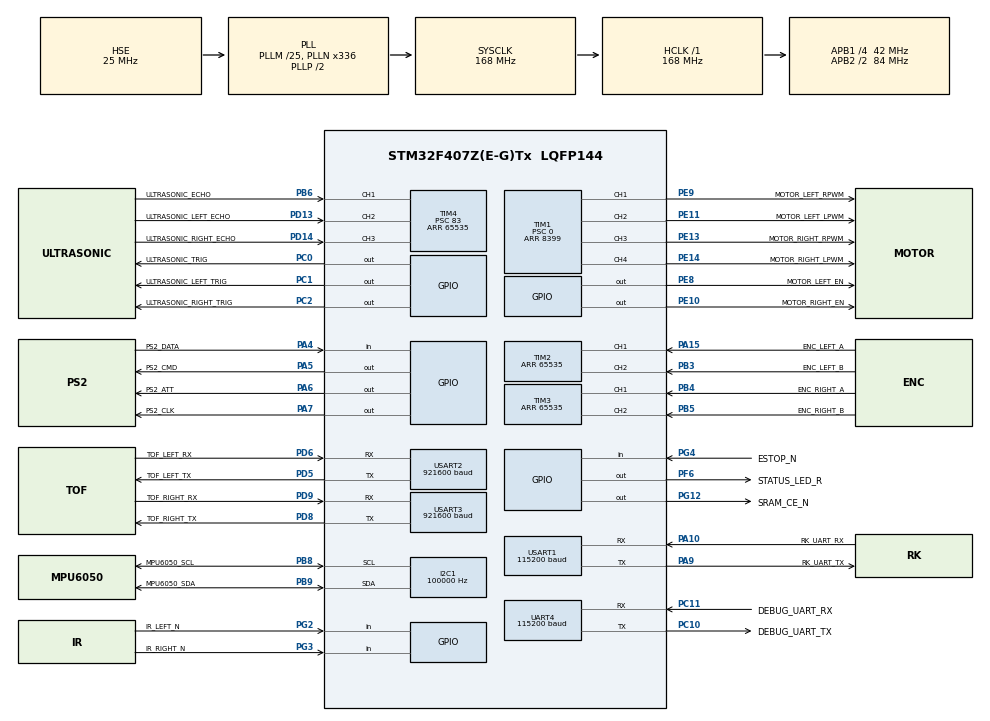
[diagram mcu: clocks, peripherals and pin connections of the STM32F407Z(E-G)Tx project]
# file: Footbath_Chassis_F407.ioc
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I2C1.Analog_Filter=I2C_ANALOGFILTER_ENABLE
I2C1.ClockSpeed=100000
I2C1.I2C_Coeff_DF=0
Mcu.Family=STM32F4
Mcu.Name=STM32F407Z(E-G)Tx
Mcu.Package=LQFP144
NVIC.PriorityGroup=NVIC_PRIORITYGROUP_4
NVIC.TIM4_IRQn=true\:7\:0\:true\:false\:true\:true\:true\:true
NVIC.UART4_IRQn=true\:6\:0\:true\:false\:true\:true\:true\:true
NVIC.USART1_IRQn=true\:5\:0\:true\:false\:true\:true\:true\:true
NVIC.USART2_IRQn=true\:6\:0\:true\:false\:true\:true\:true\:true
NVIC.USART3_IRQn=true\:6\:0\:true\:false\:true\:true\:true\:true
PA4.GPIO_Label=PS2_DATA
PA4.GPIO_PuPd=GPIO_PULLUP
PA4.Signal=GPIO_Input
PA5.GPIO_Label=PS2_CMD
PA5.GPIO_PuPd=GPIO_PULLUP
PA5.GPIO_Speed=GPIO_SPEED_FREQ_LOW
PA5.PinState=GPIO_PIN_SET
PA5.Signal=GPIO_Output
PA6.GPIO_Label=PS2_ATT
PA6.GPIO_PuPd=GPIO_PULLUP
PA6.GPIO_Speed=GPIO_SPEED_FREQ_LOW
PA6.PinState=GPIO_PIN_SET
PA6.Signal=GPIO_Output
PA7.GPIO_Label=PS2_CLK
PA7.GPIO_PuPd=GPIO_PULLUP
PA7.GPIO_Speed=GPIO_SPEED_FREQ_LOW
PA7.PinState=GPIO_PIN_SET
PA7.Signal=GPIO_Output
PA10.GPIO_Label=RK_UART_RX
PA10.Mode=Asynchronous
PA10.Signal=USART1_RX
PA13.Mode=Serial_Wire
PA13.Signal=SYS_JTMS-SWDIO
PA14.Mode=Serial_Wire
PA14.Signal=SYS_JTCK-SWCLK
PA15.GPIO_Label=ENC_LEFT_A
PA15.Signal=S_TIM2_CH1_ETR
PA9.GPIO_Label=RK_UART_TX
PA9.Mode=Asynchronous
PA9.Signal=USART1_TX
PB3.GPIO_Label=ENC_LEFT_B
PB3.Signal=S_TIM2_CH2
PB4.GPIO_Label=ENC_RIGHT_A
PB4.Signal=S_TIM3_CH1
PB5.GPIO_Label=ENC_RIGHT_B
PB5.Signal=S_TIM3_CH2
PB6.GPIO_Label=ULTRASONIC_ECHO
PB6.Signal=S_TIM4_CH1
PB8.GPIO_Label=MPU6050_SCL
PB8.Mode=I2C
PB8.Signal=I2C1_SCL
PB9.GPIO_Label=MPU6050_SDA
PB9.Mode=I2C
PB9.Signal=I2C1_SDA
PC0.GPIO_Label=ULTRASONIC_TRIG
PC0.GPIO_Speed=GPIO_SPEED_FREQ_LOW
PC0.Signal=GPIO_Output
PC1.GPIO_Label=ULTRASONIC_LEFT_TRIG
PC1.Signal=GPIO_Output
PC2.GPIO_Label=ULTRASONIC_RIGHT_TRIG
PC2.Signal=GPIO_Output
PD13.GPIO_Label=ULTRASONIC_LEFT_ECHO
PD13.GPIO_PuPd=GPIO_PULLDOWN
PD13.Signal=S_TIM4_CH2
PD14.GPIO_Label=ULTRASONIC_RIGHT_ECHO
PD14.GPIO_PuPd=GPIO_PULLDOWN
PD14.Signal=S_TIM4_CH3
PG12.GPIO_Label=SRAM_CE_N
PG12.PinState=GPIO_PIN_SET
PG12.GPIO_PuPd=GPIO_PULLUP
PG12.Signal=GPIO_Output
PC10.GPIO_Label=DEBUG_UART_TX
PC10.Mode=Asynchronous
PC10.Signal=UART4_TX
PC11.GPIO_Label=DEBUG_UART_RX
PC11.Mode=Asynchronous
PC11.Signal=UART4_RX
PD5.GPIO_Label=TOF_LEFT_TX
PD5.Mode=Asynchronous
PD5.Signal=USART2_TX
PD6.GPIO_Label=TOF_LEFT_RX
PD6.Mode=Asynchronous
PD6.Signal=USART2_RX
PD8.GPIO_Label=TOF_RIGHT_TX
PD8.Mode=Asynchronous
PD8.Signal=USART3_TX
PD9.GPIO_Label=TOF_RIGHT_RX
PD9.Mode=Asynchronous
PD9.Signal=USART3_RX
PE10.GPIO_Label=MOTOR_RIGHT_EN
PE10.GPIO_Speed=GPIO_SPEED_FREQ_LOW
PE10.Signal=GPIO_Output
PE11.GPIO_Label=MOTOR_LEFT_LPWM
PE11.Signal=S_TIM1_CH2
PE13.GPIO_Label=MOTOR_RIGHT_RPWM
PE13.Signal=S_TIM1_CH3
PE14.GPIO_Label=MOTOR_RIGHT_LPWM
PE14.Signal=S_TIM1_CH4
PE8.GPIO_Label=MOTOR_LEFT_EN
PE8.GPIO_Speed=GPIO_SPEED_FREQ_LOW
PE8.Signal=GPIO_Output
PE9.GPIO_Label=MOTOR_LEFT_RPWM
PE9.Signal=S_TIM1_CH1
PF6.GPIO_Label=STATUS_LED_R
PF6.GPIO_Speed=GPIO_SPEED_FREQ_LOW
PF6.Signal=GPIO_Output
PG2.GPIO_Label=IR_LEFT_N
PG2.GPIO_PuPd=GPIO_PULLUP
PG2.Signal=GPIO_Input
PG3.GPIO_Label=IR_RIGHT_N
PG3.GPIO_PuPd=GPIO_PULLUP
PG3.Signal=GPIO_Input
PG4.GPIO_Label=ESTOP_N
PG4.GPIO_PuPd=GPIO_PULLUP
PG4.Signal=GPIO_Input
PH0-OSC_IN.Mode=HSE-External-Oscillator
PH0-OSC_IN.Signal=RCC_OSC_IN
PH1-OSC_OUT.Mode=HSE-External-Oscillator
PH1-OSC_OUT.Signal=RCC_OSC_OUT
ProjectManager.HeapSize=0x200
ProjectManager.StackSize=0x800
ProjectManager.TargetToolchain=MDK-ARM V5.32
RCC.48MHZClocksFreq_Value=48000000
RCC.AHBFreq_Value=168000000
RCC.APB1CLKDivider=RCC_HCLK_DIV4
RCC.APB1Freq_Value=42000000
RCC.APB1TimFreq_Value=84000000
RCC.APB2CLKDivider=RCC_HCLK_DIV2
RCC.APB2Freq_Value=84000000
RCC.APB2TimFreq_Value=168000000
RCC.CortexFreq_Value=168000000
RCC.HCLKFreq_Value=168000000
RCC.HSE_VALUE=25000000
RCC.HSI_VALUE=16000000
RCC.LSE_VALUE=32768
RCC.PLLM=25
RCC.PLLN=336
RCC.PLLP=RCC_PLLP_DIV2
RCC.PLLQ=7
RCC.PLLSourceVirtual=RCC_PLLSOURCE_HSE
RCC.SYSCLKFreq_VALUE=168000000
RCC.SYSCLKSource=RCC_SYSCLKSOURCE_PLLCLK
RCC.SYSCLKSourceVirtual=RCC_SYSCLKSOURCE_PLLCLK
RCC.VCOOutputFreq_Value=336000000
SH.S_TIM1_CH1.0=TIM1_CH1,PWM Generation1 CH1
SH.S_TIM1_CH2.0=TIM1_CH2,PWM Generation2 CH2
SH.S_TIM1_CH3.0=TIM1_CH3,PWM Generation3 CH3
SH.S_TIM1_CH4.0=TIM1_CH4,PWM Generation4 CH4
SH.S_TIM2_CH1_ETR.0=TIM2_CH1,Encoder_Interface
SH.S_TIM2_CH2.0=TIM2_CH2,Encoder_Interface
SH.S_TIM3_CH1.0=TIM3_CH1,Encoder_Interface
SH.S_TIM3_CH2.0=TIM3_CH2,Encoder_Interface
SH.S_TIM4_CH1.0=TIM4_CH1,Input_Capture1_from_TI1
SH.S_TIM4_CH2.0=TIM4_CH2,Input_Capture2_from_TI2
SH.S_TIM4_CH3.0=TIM4_CH3,Input_Capture3_from_TI3
TIM1.Channel-PWM\ Generation1\ CH1=TIM_CHANNEL_1
TIM1.Channel-PWM\ Generation2\ CH2=TIM_CHANNEL_2
TIM1.Channel-PWM\ Generation3\ CH3=TIM_CHANNEL_3
TIM1.Channel-PWM\ Generation4\ CH4=TIM_CHANNEL_4
TIM1.Period=8399
TIM1.Prescaler=0
TIM2.EncoderMode=TIM_ENCODERMODE_TI12
TIM2.IC1Filter=6
TIM2.IC2Filter=6
TIM2.Period=65535
TIM3.EncoderMode=TIM_ENCODERMODE_TI12
TIM3.IC1Filter=6
TIM3.IC2Filter=6
TIM3.Period=65535
TIM4.Channel-Input_Capture1_from_TI1=TIM_CHANNEL_1
TIM4.Channel-Input_Capture2_from_TI2=TIM_CHANNEL_2
TIM4.Channel-Input_Capture3_from_TI3=TIM_CHANNEL_3
TIM4.Period=65535
TIM4.Prescaler=83
UART4.BaudRate=115200
UART4.VirtualMode=Asynchronous
UART4.VirtualMode-Asynchronous=VM_ASYNC
USART1.BaudRate=115200
USART1.VirtualMode=VM_ASYNC
USART1.VirtualMode-Asynchronous=VM_ASYNC
USART2.BaudRate=921600
USART2.VirtualMode=VM_ASYNC
USART2.VirtualMode-Asynchronous=VM_ASYNC
USART3.BaudRate=921600
USART3.VirtualMode=VM_ASYNC
USART3.VirtualMode-Asynchronous=VM_ASYNC
board=custom

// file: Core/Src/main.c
/* USER CODE BEGIN Header */
/**
  ******************************************************************************
  * @file           : main.c
  * @brief          : Main program body
  ******************************************************************************
  * @attention
  *
  * Copyright (c) 2026 STMicroelectronics.
  * All rights reserved.
  *
  * This software is licensed under terms that can be found in the LICENSE file
  * in the root directory of this software component.
  * If no LICENSE file comes with this software, it is provided AS-IS.
  *
  ******************************************************************************
  */
/* USER CODE END Header */
#include "main.h"
#include "i2c.h"
#include "tim.h"
#include "usart.h"
#include "gpio.h"

/* USER CODE BEGIN Includes */
#include "board.h"
#include "chassis_app.h"
#include "chassis_tasks.h"
/* USER CODE END Includes */

void SystemClock_Config(void);

int main(void)
{

  /* MCU Configuration--------------------------------------------------------*/

  /* Reset of all peripherals, Initializes the Flash interface and the Systick. */
  HAL_Init();

  /* Configure the system clock */
  SystemClock_Config();

  /* Initialize all configured peripherals */
  MX_GPIO_Init();
  MX_I2C1_Init();
  MX_TIM1_Init();
  MX_TIM2_Init();
  MX_TIM3_Init();
  MX_TIM4_Init();
  MX_USART1_UART_Init();
  MX_USART2_UART_Init();
  MX_USART3_UART_Init();
  MX_UART4_Init();
  /* USER CODE BEGIN 2 */
  chassis_app_init();
  chassis_tasks_start();
  /* USER CODE END 2 */

  /* Infinite loop */
  while (1)
  {

    /* USER CODE BEGIN 3 */
    board_fatal_error();
  }
  /* USER CODE END 3 */
}

void SystemClock_Config(void)
{
  RCC_OscInitTypeDef RCC_OscInitStruct = {0};
  RCC_ClkInitTypeDef RCC_ClkInitStruct = {0};

  /** Configure the main internal regulator output voltage
  */
  __HAL_RCC_PWR_CLK_ENABLE();
  __HAL_PWR_VOLTAGESCALING_CONFIG(PWR_REGULATOR_VOLTAGE_SCALE1);

  /** Initializes the RCC Oscillators according to the specified parameters
  * in the RCC_OscInitTypeDef structure.
  */
  RCC_OscInitStruct.OscillatorType = RCC_OSCILLATORTYPE_HSE;
  RCC_OscInitStruct.HSEState = RCC_HSE_ON;
  RCC_OscInitStruct.PLL.PLLState = RCC_PLL_ON;
  RCC_OscInitStruct.PLL.PLLSource = RCC_PLLSOURCE_HSE;
  RCC_OscInitStruct.PLL.PLLM = 25;
  RCC_OscInitStruct.PLL.PLLN = 336;
  RCC_OscInitStruct.PLL.PLLP = RCC_PLLP_DIV2;
  RCC_OscInitStruct.PLL.PLLQ = 7;
  if (HAL_RCC_OscConfig(&RCC_OscInitStruct) != HAL_OK)
  {
    Error_Handler();
  }

  /** Initializes the CPU, AHB and APB buses clocks
  */
  RCC_ClkInitStruct.ClockType = RCC_CLOCKTYPE_HCLK|RCC_CLOCKTYPE_SYSCLK
                              |RCC_CLOCKTYPE_PCLK1|RCC_CLOCKTYPE_PCLK2;
  RCC_ClkInitStruct.SYSCLKSource = RCC_SYSCLKSOURCE_PLLCLK;
  RCC_ClkInitStruct.AHBCLKDivider = RCC_SYSCLK_DIV1;
  RCC_ClkInitStruct.APB1CLKDivider = RCC_HCLK_DIV4;
  RCC_ClkInitStruct.APB2CLKDivider = RCC_HCLK_DIV2;

  if (HAL_RCC_ClockConfig(&RCC_ClkInitStruct, FLASH_LATENCY_5) != HAL_OK)
  {
    Error_Handler();
  }
}

void Error_Handler(void)
{
  /* USER CODE BEGIN Error_Handler_Debug */
  board_fatal_error();
  /* USER CODE END Error_Handler_Debug */
}
